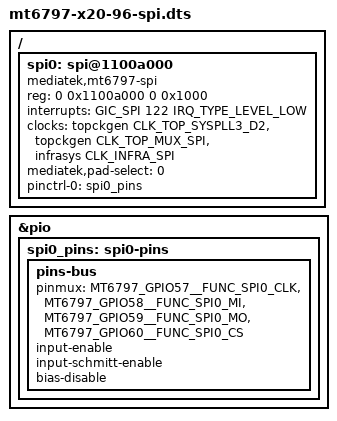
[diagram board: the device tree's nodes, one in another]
// SPDX-License-Identifier: GPL-2.0-only
/* MT6797 SPI controller and pin configuration for X20-96. */
/dts-v1/;

#include "mt6797-x20-96-i2c.dts"

/ {
	spi0: spi@1100a000 {
		compatible = "mediatek,mt6797-spi";
		reg = <0 0x1100a000 0 0x1000>;
		interrupts = <GIC_SPI 122 IRQ_TYPE_LEVEL_LOW>;
		clocks = <&topckgen CLK_TOP_SYSPLL3_D2>,
			 <&topckgen CLK_TOP_MUX_SPI>, <&infrasys CLK_INFRA_SPI>;
		clock-names = "parent-clk", "sel-clk", "spi-clk";
		mediatek,pad-select = <0>;
		pinctrl-names = "default";
		pinctrl-0 = <&spi0_pins>;
		#address-cells = <1>;
		#size-cells = <0>;

	};
};

&pio {
	spi0_pins: spi0-pins {
		pins-bus {
			pinmux = <MT6797_GPIO57__FUNC_SPI0_CLK>,
				 <MT6797_GPIO58__FUNC_SPI0_MI>,
				 <MT6797_GPIO59__FUNC_SPI0_MO>,
				 <MT6797_GPIO60__FUNC_SPI0_CS>;
			input-enable;
			input-schmitt-enable;
			bias-disable;
		};
	};
};
